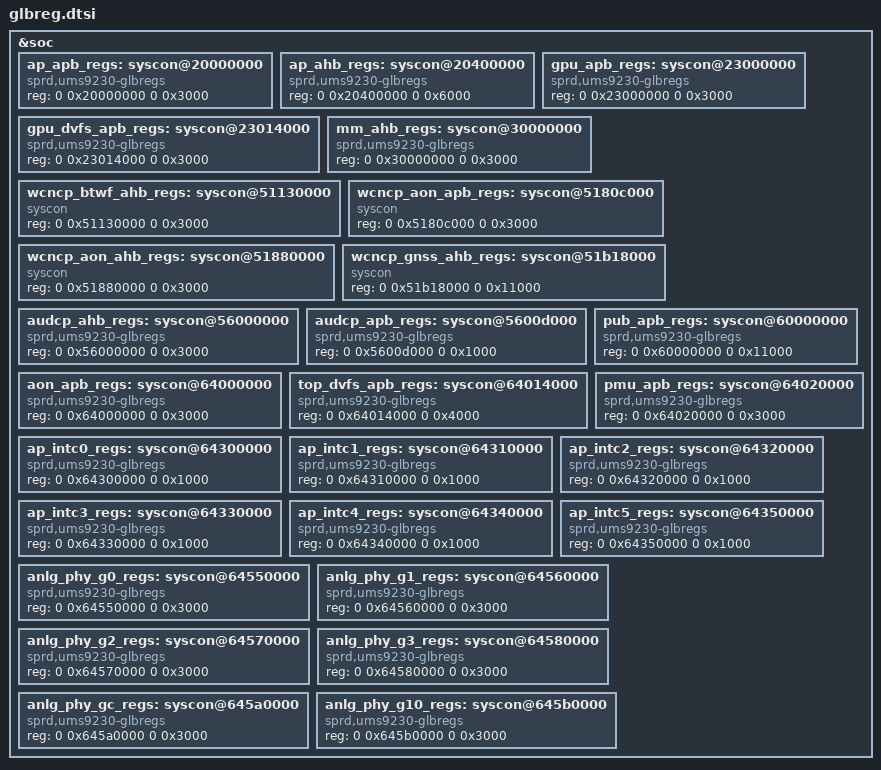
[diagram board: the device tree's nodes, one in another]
// SPDX-License-Identifier: (GPL-2.0+ OR MIT)
/*
 * Copyright (C) 2020, Unisoc Inc.
 */

&soc {
	ap_apb_regs: syscon@20000000 {
		compatible = "sprd,ums9230-glbregs", "syscon";
		#syscon-cells = <2>;
		reg = <0 0x20000000 0 0x3000>;
	};

	ap_ahb_regs: syscon@20400000 {
		compatible = "sprd,ums9230-glbregs", "syscon";
		#syscon-cells = <2>;
		reg = <0 0x20400000 0 0x6000>;
	};


	gpu_apb_regs: syscon@23000000 {
		compatible = "sprd,ums9230-glbregs", "syscon";
		#syscon-cells = <2>;
		reg = <0 0x23000000 0 0x3000>;
	};

	gpu_dvfs_apb_regs: syscon@23014000 {
		compatible = "sprd,ums9230-glbregs", "syscon";
		#syscon-cells = <2>;
		reg = <0 0x23014000 0 0x3000>;
	};

	mm_ahb_regs: syscon@30000000 {
		compatible = "sprd,ums9230-glbregs", "syscon";
		#syscon-cells = <2>;
		reg = <0 0x30000000 0 0x3000>;
	};

	wcncp_btwf_ahb_regs: syscon@51130000 {
		compatible = "syscon";
		#syscon-cells = <2>;
		reg = <0 0x51130000 0 0x3000>;
	};
	wcncp_aon_apb_regs: syscon@5180c000 {
		compatible = "syscon";
		#syscon-cells = <2>;
		reg = <0 0x5180c000 0 0x3000>;
	};
	wcncp_aon_ahb_regs: syscon@51880000 {
		compatible = "syscon";
		#syscon-cells = <2>;
		reg = <0 0x51880000 0 0x3000>;
	};

	wcncp_gnss_ahb_regs: syscon@51b18000 {
		compatible = "syscon";
		#syscon-cells = <2>;
		reg = <0 0x51b18000 0 0x11000>;
	};

	audcp_ahb_regs: syscon@56000000 {
		compatible = "sprd,ums9230-glbregs", "syscon";
		#syscon-cells = <2>;
		reg = <0 0x56000000 0 0x3000>;
	};

	audcp_apb_regs: syscon@5600d000 {
		compatible = "sprd,ums9230-glbregs", "syscon";
		#syscon-cells = <2>;
		reg = <0 0x5600d000 0 0x1000>;
	};

	pub_apb_regs: syscon@60000000 {
		compatible = "sprd,ums9230-glbregs", "syscon";
		#syscon-cells = <2>;
		reg = <0 0x60000000 0 0x11000>;
	};

	aon_apb_regs: syscon@64000000 {
		compatible = "sprd,ums9230-glbregs", "syscon";
		#syscon-cells = <2>;
		reg = <0 0x64000000 0 0x3000>;
	};

	top_dvfs_apb_regs: syscon@64014000 {
		compatible = "sprd,ums9230-glbregs", "syscon";
		reg = <0 0x64014000 0 0x4000>;
	};

	pmu_apb_regs: syscon@64020000 {
		compatible = "sprd,ums9230-glbregs", "syscon";
		#syscon-cells = <2>;
		reg = <0 0x64020000 0 0x3000>;
	};

	ap_intc0_regs: syscon@64300000 {
		compatible = "sprd,ums9230-glbregs", "syscon";
		#syscon-cells = <2>;
		reg = <0 0x64300000 0 0x1000>;
	};

	ap_intc1_regs: syscon@64310000 {
		compatible = "sprd,ums9230-glbregs", "syscon";
		#syscon-cells = <2>;
		reg = <0 0x64310000 0 0x1000>;
	};

	ap_intc2_regs: syscon@64320000 {
		compatible = "sprd,ums9230-glbregs", "syscon";
		#syscon-cells = <2>;
		reg = <0 0x64320000 0 0x1000>;
	};

	ap_intc3_regs: syscon@64330000 {
		compatible = "sprd,ums9230-glbregs", "syscon";
		#syscon-cells = <2>;
		reg = <0 0x64330000 0 0x1000>;
	};

	ap_intc4_regs: syscon@64340000 {
		compatible = "sprd,ums9230-glbregs", "syscon";
		#syscon-cells = <2>;
		reg = <0 0x64340000 0 0x1000>;
	};

	ap_intc5_regs: syscon@64350000 {
		compatible = "sprd,ums9230-glbregs", "syscon";
		#syscon-cells = <2>;
		reg = <0 0x64350000 0 0x1000>;
	};

	anlg_phy_g0_regs: syscon@64550000 {
		compatible = "sprd,ums9230-glbregs", "syscon";
		#syscon-cells = <2>;
		reg = <0 0x64550000 0 0x3000>;
	};

	anlg_phy_g1_regs: syscon@64560000 {
		compatible = "sprd,ums9230-glbregs", "syscon";
		#syscon-cells = <2>;
		reg = <0 0x64560000 0 0x3000>;
	};

	anlg_phy_g2_regs: syscon@64570000 {
		compatible = "sprd,ums9230-glbregs", "syscon";
		#syscon-cells = <2>;
		reg = <0 0x64570000 0 0x3000>;
	};

	anlg_phy_g3_regs: syscon@64580000 {
		compatible = "sprd,ums9230-glbregs", "syscon";
		#syscon-cells = <2>;
		reg = <0 0x64580000 0 0x3000>;
	};

	anlg_phy_gc_regs: syscon@645a0000 {
		compatible = "sprd,ums9230-glbregs", "syscon";
		#syscon-cells = <2>;
		reg = <0 0x645a0000 0 0x3000>;
	};

	anlg_phy_g10_regs: syscon@645b0000 {
		compatible = "sprd,ums9230-glbregs", "syscon";
		#syscon-cells = <2>;
		reg = <0 0x645b0000 0 0x3000>;
	};
};
